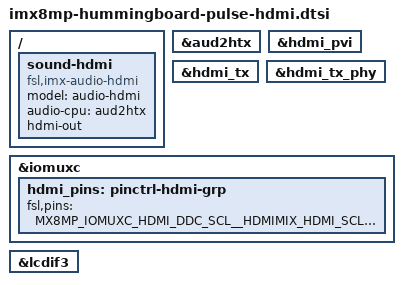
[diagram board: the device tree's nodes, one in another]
// SPDX-License-Identifier: (GPL-2.0+ OR MIT)
/*
 * Copyright 2025 Josua Mayer <josua@solid-run.com>
 */

/ {
	sound-hdmi {
		compatible = "fsl,imx-audio-hdmi";
		model = "audio-hdmi";
		audio-cpu = <&aud2htx>;
		hdmi-out;
	};
};

&aud2htx {
	status = "okay";
};

&hdmi_pvi {
	status = "okay";
};

&hdmi_tx {
	status = "okay";
};

&hdmi_tx_phy {
	status = "okay";
};

&iomuxc {
	hdmi_pins: pinctrl-hdmi-grp {
		fsl,pins = <
			MX8MP_IOMUXC_HDMI_DDC_SCL__HDMIMIX_HDMI_SCL	0x400001c3
			MX8MP_IOMUXC_HDMI_DDC_SDA__HDMIMIX_HDMI_SDA	0x400001c3
			MX8MP_IOMUXC_HDMI_CEC__HDMIMIX_HDMI_CEC		0x154
			MX8MP_IOMUXC_HDMI_HPD__HDMIMIX_HDMI_HPD		0x154
		>;
	};
};

&lcdif3 {
	status = "okay";
};
